# myChip register map
Vendor: ARM Ltd.; Series: ARMCM3; File version: 1.2
CPU: CM3 r2p1, little endian, no MPU, no FPU, 3 interrupt priority bits
Registers are 32-bit, read-write, reset 0x0 unless marked. A register's access mark holds for its fields unless they carry their own. Offsets are from the block's base; [hi:lo] are bit positions; {n}, {i} and the like mark numbered series.

## HRPWM_SLV0
Base 0x4003B100
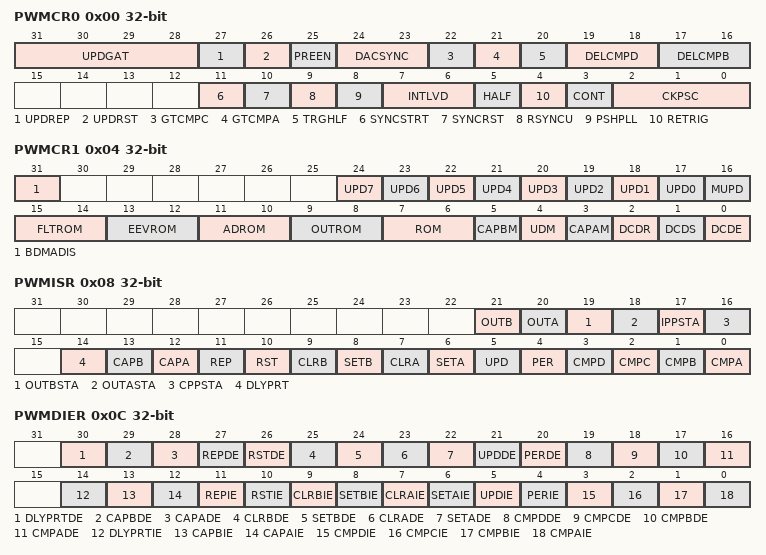
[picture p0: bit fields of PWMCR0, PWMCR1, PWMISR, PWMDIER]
0x00 PWMCR0 — HRPWM PWMx Control Register0
  [31:28] UPDGAT — 更新门控
  [27] UPDREP — PWMx Repetition 更新
  [26] UPDRST — PWMx Reset 更新
  [25] PREEN — PWMx 预加载使能
  [24:23] DACSYNC — DAC Trigger同步
  [22] GTCMPC — PWMx CMPC Greater Than 模式
  [21] GTCMPA — PWMx CMPA Greater Than 模式
  [20] TRGHLF — PWMx Triggered-half 模式
  [19:18] DELCMPD — PWMx CMPD Auto-Delayed 模式
  [17:16] DELCMPB — PWMx CMPB Auto-Delayed 模式
  [11] SYNCSTRT — 同步事件启动 PWMx
  [10] SYNCRST — 同步事件复位 PWMx
  [9] RSYNCU — PWMx 重同步更新
  [8] PSHPLL — PWMx Push-pull 模式
  [7:6] INTLVD — PWMx Interleaved 模式
  [5] HALF — PWMx Half 模式
  [4] RETRIG — PWMx 可重触发模式
  [3] CONT — PWMx 连续模式
  [2:0] CKPSC — PWMx 时钟预分频比
0x04 PWMCR1 — HRPWM PWMx Control Register1
  [31] BDMADIS — PWMx Burst DMA 禁止
  [n+17] UPD{n} (n=0..7) — PWM{n} 更新
  [16] MUPD — Master PWM 更新
  [15:14] FLTROM — 故障 Roll-Over 模式选择
  [13:12] EEVROM — 事件 Roll-Over 模式选择
  [11:10] ADROM — ADC Roll-Over 模式选择
  [9:8] OUTROM — 输出 Roll-Over 模式选择
  [7:6] ROM — Roll-Over 模式选择
  [5] CAPBM — Capture B 模式选择
  [4] UDM — Up-Down 模式选择
  [3] CAPAM — Capture A 模式选择
  [2] DCDR — DAC Reset Trigger 来源
  [1] DCDS — DAC Step Trigger 来源
  [0] DCDE — DAC Reset／Step Trigger 使能
0x08 PWMISR — HRPWM PWMx Interrupt Status Register
  [21] OUTB ro — OUTB 当前输出（输出级之前）
  [20] OUTA ro — OUTA 当前输出（输出级之前）
  [19] OUTBSTA ro — OUTB 输出状态（延迟空闲保护发生时）
  [18] OUTASTA ro — OUTA 输出状态（延迟空闲保护发生时）
  [17] IPPSTA ro — PushPull 输出状态（延迟空闲/均衡空闲保护发生时）
  [16] CPPSTA ro — PushPull 当前状态
  [14] DLYPRT — Delayed Protection 中断标志
  [13] CAPB — Capture B 中断标志
  [12] CAPA — Capture A 中断标志
  [11] REP — Repetition 中断标志
  [10] RST — Reset 中断标志
  [9] CLRB — Out B Clear 中断标志
  [8] SETB — Out B Set 中断标志
  [7] CLRA — Out A Clear 中断标志
  [6] SETA — Out A Set 中断标志
  [5] UPD — Update 中断标志
  [4] PER — Roll-Over 中断标志
  [3] CMPD — Compare D 中断标志
  [2] CMPC — Compare C 中断标志
  [1] CMPB — Compare B 中断标志
  [0] CMPA — Compare A 中断标志
0x0C PWMDIER — HRPWM PWMx DMA Interrupt Enable Register
  [30] DLYPRTDE — Delayed Protection DMA使能
  [29] CAPBDE — Capture B DMA使能
  [28] CAPADE — Capture A DMA使能
  [27] REPDE — Repetition DMA使能
  [26] RSTDE — Reset DMA使能
  [25] CLRBDE — Out B Clear DMA使能
  [24] SETBDE — Out B Set DMA使能
  [23] CLRADE — Out A Clear DMA使能
  [22] SETADE — Out A Set DMA使能
  [21] UPDDE — Update DMA使能
  [20] PERDE — Roll-Over DMA使能
  [19] CMPDDE — Compare D DMA使能
  [18] CMPCDE — Compare C DMA使能
  [17] CMPBDE — Compare B DMA使能
  [16] CMPADE — Compare A DMA使能
  [14] DLYPRTIE — Delayed Protection 中断使能
  [13] CAPBIE — Capture B 中断使能
  [12] CAPAIE — Capture A 中断使能
  [11] REPIE — Repetition 中断使能
  [10] RSTIE — Reset 中断使能
  [9] CLRBIE — Out B Clear 中断使能
  [8] SETBIE — Out B Set 中断使能
  [7] CLRAIE — Out A Clear 中断使能
  [6] SETAIE — Out A Set 中断使能
  [5] UPDIE — Update 中断使能
  [4] PERIE — Roll-Over 中断使能
  [3] CMPDIE — Compare D 中断使能
  [2] CMPCIE — Compare C 中断使能
  [1] CMPBIE — Compare B 中断使能
  [0] CMPAIE — Compare A 中断使能
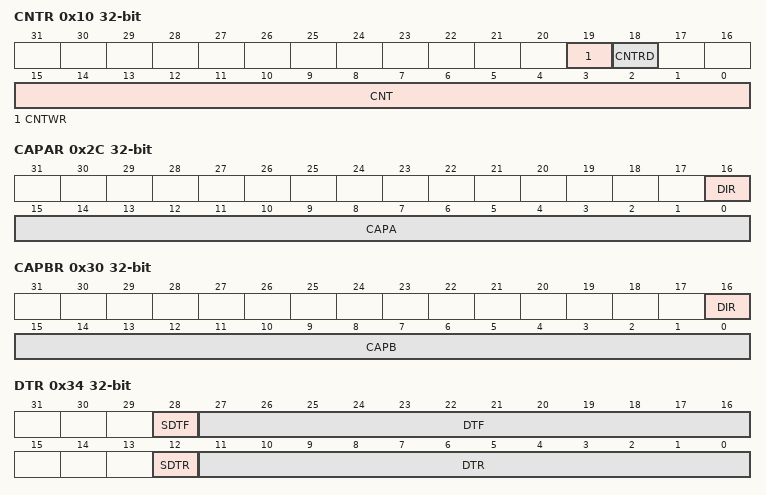
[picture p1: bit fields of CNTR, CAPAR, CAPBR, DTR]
0x10 CNTR — HRPWM PWMx Counter Register
  [19] CNTWR — PWMx Counter 写入
  [18] CNTRD — PWMx Counter 读取
  [15:0] CNT — PWMx Counter 数值
0x14 PERR — HRPWM PWMx Period Register
  [15:0] PER — PWMx Period 数值
0x18 REPR — HRPWM PWMx Repetition Register
  [7:0] REP — PWMx Repetition Period 数值
0x1C CMPAR — HRPWM PWMx Compare A Register
  [15:0] CMPA — PWMx Compare A 数值
0x20 CMPBR — HRPWM PWMx Compare B Register
  [15:0] CMPB — PWMx Compare B 数值
0x24 CMPCR — HRPWM PWMx Compare C Register
  [15:0] CMPC — PWMx Compare C 数值
0x28 CMPDR — HRPWM PWMx Compare D Register
  [15:0] CMPD — PWMx Compare D 数值
0x2C CAPAR — HRPWM PWMx Capture A Register
  [16] DIR ro — 捕获 A 方向
  [15:0] CAPA ro — 捕获 A 数值
0x30 CAPBR — HRPWM PWMx Capture B Register
  [16] DIR ro — 捕获 B 方向
  [15:0] CAPB ro — 捕获 B 数值
0x34 DTR — HRPWM PWMx DeadTime Register
  [28] SDTF — 下降沿死区符号
  [27:16] DTF — 下降沿死区时间
  [12] SDTR — 上升沿死区符号
  [11:0] DTR — 上升沿死区时间
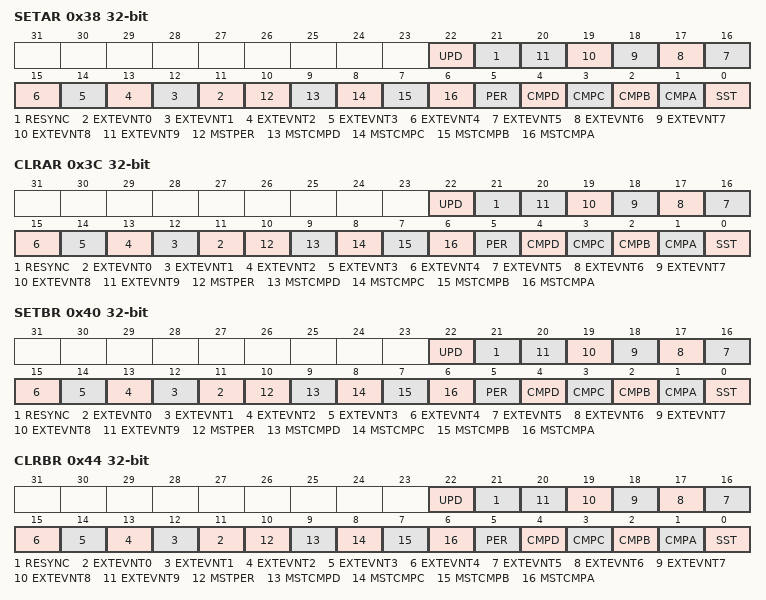
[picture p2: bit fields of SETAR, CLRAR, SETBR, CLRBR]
0x38 SETAR — HRPWM PWMx Output A Set Register
  [22] UPD — PWMx Update 事件使 PWMx Out A进入有效状态
  [21] RESYNC — Sync Input Event 事件使 PWMx Out A进入有效状态
  [n+11] EXTEVNT{n} (n=0..9) — PWMx Event {n} 事件使 PWMx Out A进入有效状态
  [10] MSTPER — Master PWM Period 事件使 PWMx Out A进入有效状态
  [9] MSTCMPD — Master PWM Compare D 事件使 PWMx Out A进入有效状态
  [8] MSTCMPC — Master PWM Compare C 事件使 PWMx Out A进入有效状态
  [7] MSTCMPB — Master PWM Compare B 事件使 PWMx Out A进入有效状态
  [6] MSTCMPA — Master PWM Compare A 事件使 PWMx Out A进入有效状态
  [5] PER — PWMx Roll-Over 事件使 PWMx Out A进入有效状态
  [4] CMPD — PWMx Compare D 事件使 PWMx Out A进入有效状态
  [3] CMPC — PWMx Compare C 事件使 PWMx Out A进入有效状态
  [2] CMPB — PWMx Compare B 事件使 PWMx Out A进入有效状态
  [1] CMPA — PWMx Compare A 事件使 PWMx Out A进入有效状态
  [0] SST — Software Set Trigger 事件使 PWMx Out A进入有效状态
0x3C CLRAR — HRPWM PWMx Output A Clear Register
  [22] UPD — PWMx Update 事件使 PWMx Out A进入无效状态
  [21] RESYNC — Sync Input Event 事件使 PWMx Out A进入无效状态
  [n+11] EXTEVNT{n} (n=0..9) — PWMx Event {n} 事件使 PWMx Out A进入无效状态
  [10] MSTPER — Master PWM Period 事件使 PWMx Out A进入无效状态
  [9] MSTCMPD — Master PWM Compare D 事件使 PWMx Out A进入无效状态
  [8] MSTCMPC — Master PWM Compare C 事件使 PWMx Out A进入无效状态
  [7] MSTCMPB — Master PWM Compare B 事件使 PWMx Out A进入无效状态
  [6] MSTCMPA — Master PWM Compare A 事件使 PWMx Out A进入无效状态
  [5] PER — PWMx Roll-Over 事件使 PWMx Out A进入无效状态
  [4] CMPD — PWMx Compare D 事件使 PWMx Out A进入无效状态
  [3] CMPC — PWMx Compare C 事件使 PWMx Out A进入无效状态
  [2] CMPB — PWMx Compare B 事件使 PWMx Out A进入无效状态
  [1] CMPA — PWMx Compare A 事件使 PWMx Out A进入无效状态
  [0] SST — Software Set Trigger 事件使 PWMx Out A进入无效状态
0x40 SETBR — HRPWM PWMx Output B Set Register
  [22] UPD — PWMx Update 事件使 PWMx Out B进入有效状态
  [21] RESYNC — Sync Input Event 事件使 PWMx Out B进入有效状态
  [n+11] EXTEVNT{n} (n=0..9) — PWMx Event {n} 事件使 PWMx Out B进入有效状态
  [10] MSTPER — Master PWM Period 事件使 PWMx Out B进入有效状态
  [9] MSTCMPD — Master PWM Compare D 事件使 PWMx Out B进入有效状态
  [8] MSTCMPC — Master PWM Compare C 事件使 PWMx Out B进入有效状态
  [7] MSTCMPB — Master PWM Compare B 事件使 PWMx Out B进入有效状态
  [6] MSTCMPA — Master PWM Compare A 事件使 PWMx Out B进入有效状态
  [5] PER — PWMx Roll-Over 事件使 PWMx Out B进入有效状态
  [4] CMPD — PWMx Compare D 事件使 PWMx Out B进入有效状态
  [3] CMPC — PWMx Compare C 事件使 PWMx Out B进入有效状态
  [2] CMPB — PWMx Compare B 事件使 PWMx Out B进入有效状态
  [1] CMPA — PWMx Compare A 事件使 PWMx Out B进入有效状态
  [0] SST — Software Set Trigger 事件使 PWMx Out B进入有效状态
0x44 CLRBR — HRPWM PWMx Output B Clear Register
  [22] UPD — PWMx Update 事件使 PWMx Out B进入无效状态
  [21] RESYNC — Sync Input Event 事件使 PWMx Out B进入无效状态
  [n+11] EXTEVNT{n} (n=0..9) — PWMx Event {n} 事件使 PWMx Out B进入无效状态
  [10] MSTPER — Master PWM Period 事件使 PWMx Out B进入无效状态
  [9] MSTCMPD — Master PWM Compare D 事件使 PWMx Out B进入无效状态
  [8] MSTCMPC — Master PWM Compare C 事件使 PWMx Out B进入无效状态
  [7] MSTCMPB — Master PWM Compare B 事件使 PWMx Out B进入无效状态
  [6] MSTCMPA — Master PWM Compare A 事件使 PWMx Out B进入无效状态
  [5] PER — PWMx Roll-Over 事件使 PWMx Out B进入无效状态
  [4] CMPD — PWMx Compare D 事件使 PWMx Out B进入无效状态
  [3] CMPC — PWMx Compare C 事件使 PWMx Out B进入无效状态
  [2] CMPB — PWMx Compare B 事件使 PWMx Out B进入无效状态
  [1] CMPA — PWMx Compare A 事件使 PWMx Out B进入无效状态
  [0] SST — Software Set Trigger 事件使 PWMx Out B进入无效状态
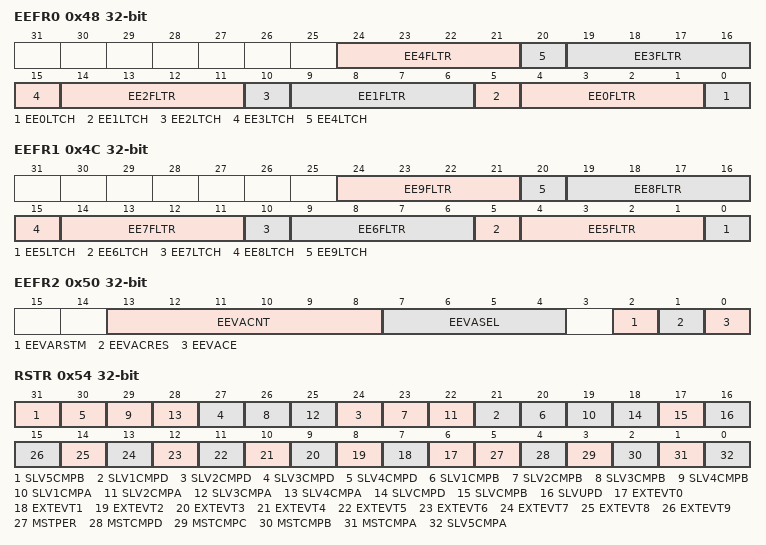
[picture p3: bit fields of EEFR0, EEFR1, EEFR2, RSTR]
0x48 EEFR0 — HRPWM PWMx External Event Register0
  [5n+4:5n+1] EE{n}FLTR (n=0..4) — Event {n} 滤波位
  [5n] EE{n}LTCH (n=0..4) — Event {n} 锁存位
0x4C EEFR1 — HRPWM PWMx External Event Register1
  [5n-21:5n-24] EE{n}FLTR (n=5..9) — Event {n} 滤波位
  [5n-25] EE{n}LTCH (n=5..9) — Event {n} 锁存位
0x50 EEFR2 — HRPWM PWMx External Event Register2
  [13:8] EEVACNT — Event A 计数阈值
  [7:4] EEVASEL — Event A 来源选择
  [2] EEVARSTM — Event A计数复位模式
  [1] EEVACRES — Event A 计数复位
  [0] EEVACE — Event A 计数使能
0x54 RSTR — HRPWM PWMx Reset Register
  [31] SLV5CMPB — PWM5 Compare B事件使 PWMx 计数器复位
  [3n+18] SLV{n}CMPD (n=1..4) — PWM{n} Compare D事件使 PWMx 计数器复位
  [3n+17] SLV{n}CMPB (n=1..4) — PWM{n} Compare B事件使 PWMx 计数器复位
  [3n+16] SLV{n}CMPA (n=1..4) — PWM{n} Compare A事件使 PWMx 计数器复位
  [18] SLVCMPD — PWMx Compare D事件使 PWMx 计数器复位
  [17] SLVCMPB — PWMx Compare B事件使 PWMx 计数器复位
  [16] SLVUPD — PWMx Update事件使 PWMx 计数器复位
  [n+6] EXTEVT{n} (n=0..9) — PWMx Event {n}事件使 PWMx 计数器复位
  [5] MSTPER — Master PWM Period事件使 PWMx 计数器复位
  [4] MSTCMPD — Master PWM Compare D事件使 PWMx 计数器复位
  [3] MSTCMPC — Master PWM Compare C事件使 PWMx 计数器复位
  [2] MSTCMPB — Master PWM Compare B事件使 PWMx 计数器复位
  [1] MSTCMPA — Master PWM Compare A事件使 PWMx 计数器复位
  [0] SLV5CMPA — PWM5 Compare A事件使 PWMx 计数器复位
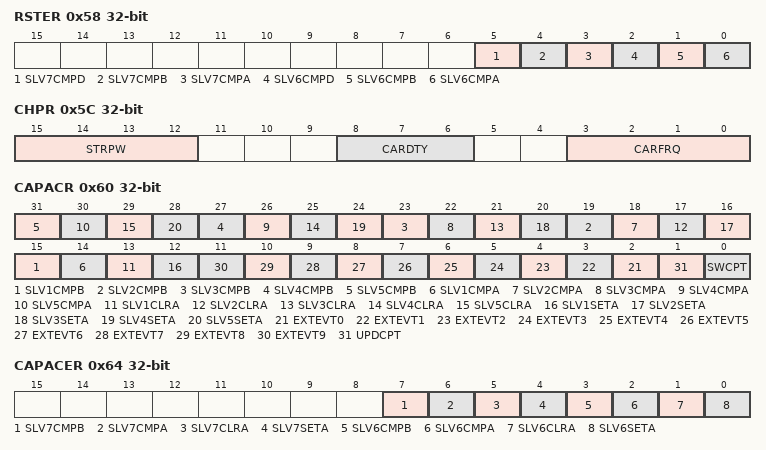
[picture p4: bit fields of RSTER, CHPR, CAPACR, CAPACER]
0x58 RSTER — HRPWM PWMx Reset Extended Register
  [5] SLV7CMPD — PWM7 Compare D事件使 PWMx 计数器复位
  [4] SLV7CMPB — PWM7 Compare B事件使 PWMx 计数器复位
  [3] SLV7CMPA — PWM7 Compare A事件使 PWMx 计数器复位
  [2] SLV6CMPD — PWM6 Compare D事件使 PWMx 计数器复位
  [1] SLV6CMPB — PWM6 Compare B事件使 PWMx 计数器复位
  [0] SLV6CMPA — PWM6 Compare A事件使 PWMx 计数器复位
0x5C CHPR — HRPWM PWMx Chopper Register
  [15:12] STRPW — PWMx 启动脉冲宽度
  [8:6] CARDTY — PWMx 斩波占空比值
  [3:0] CARFRQ — PWMx 载波频率值
0x60 CAPACR — HRPWM PWMx Capture A Control Register
  [4n+11] SLV{n}CMPB (n=1..5) — PWM{n} Compare B 事件触发 Capture A 事件
  [4n+10] SLV{n}CMPA (n=1..5) — PWM{n} Compare A 事件触发 Capture A 事件
  [4n+9] SLV{n}CLRA (n=1..5) — PWM{n} OutA Clr 事件触发 Capture A 事件
  [4n+8] SLV{n}SETA (n=1..5) — PWM{n} OutA Set 事件触发 Capture A 事件
  [n+2] EXTEVT{n} (n=0..9) — PWMx Event {n} 事件触发 Capture A 事件
  [1] UPDCPT — PWMx Update 事件触发 Capture A 事件
  [0] SWCPT — Software Capture 事件触发 Capture A 事件
0x64 CAPACER — HRPWM PWMx Capture A Control Extended Register
  [7] SLV7CMPB — PWM7 Compare B 事件触发 Capture A 事件
  [6] SLV7CMPA — PWM7 Compare A 事件触发 Capture A 事件
  [5] SLV7CLRA — PWM7 OutA Clr 事件触发 Capture A 事件
  [4] SLV7SETA — PWM7 OutA Set 事件触发 Capture A 事件
  [3] SLV6CMPB — PWM6 Compare B 事件触发 Capture A 事件
  [2] SLV6CMPA — PWM6 Compare A 事件触发 Capture A 事件
  [1] SLV6CLRA — PWM6 OutA Clr 事件触发 Capture A 事件
  [0] SLV6SETA — PWM6 OutA Set 事件触发 Capture A 事件
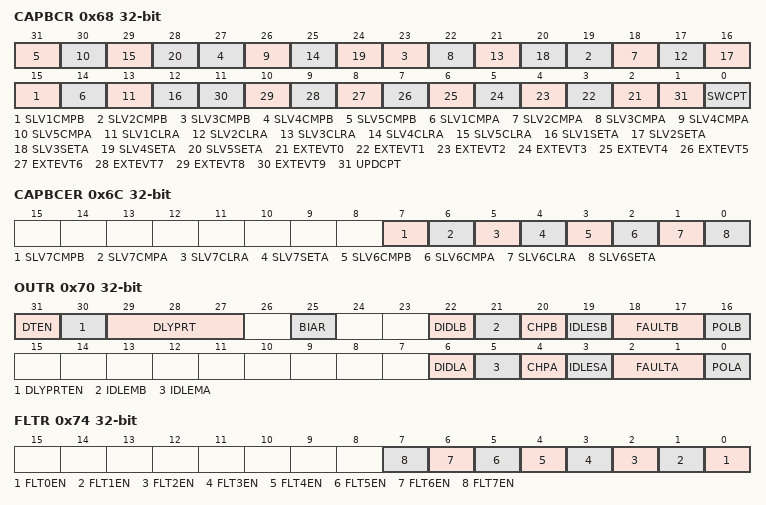
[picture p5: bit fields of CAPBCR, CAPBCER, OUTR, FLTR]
0x68 CAPBCR — HRPWM PWMx Capture B Control Register
  [4n+11] SLV{n}CMPB (n=1..5) — PWM{n} Compare B 事件触发 Capture B 事件
  [4n+10] SLV{n}CMPA (n=1..5) — PWM{n} Compare A 事件触发 Capture B 事件
  [4n+9] SLV{n}CLRA (n=1..5) — PWM{n} OutA Clr 事件触发 Capture B 事件
  [4n+8] SLV{n}SETA (n=1..5) — PWM{n} OutA Set 事件触发 Capture B 事件
  [n+2] EXTEVT{n} (n=0..9) — PWMx Event {n} 事件触发 Capture B 事件
  [1] UPDCPT — PWMx Update 事件触发 Capture B 事件
  [0] SWCPT — Software Capture 事件触发 Capture B 事件
0x6C CAPBCER — HRPWM PWMx Capture B Control Extended Register
  [7] SLV7CMPB — PWM7 Compare B 事件触发 Capture B 事件
  [6] SLV7CMPA — PWM7 Compare A 事件触发 Capture B 事件
  [5] SLV7CLRA — PWM7 OutA Clr 事件触发 Capture B 事件
  [4] SLV7SETA — PWM7 OutA Set 事件触发 Capture B 事件
  [3] SLV6CMPB — PWM6 Compare B 事件触发 Capture B 事件
  [2] SLV6CMPA — PWM6 Compare A 事件触发 Capture B 事件
  [1] SLV6CLRA — PWM6 OutA Clr 事件触发 Capture B 事件
  [0] SLV6SETA — PWM6 OutA Set 事件触发 Capture B 事件
0x70 OUTR — HRPWM PWMx Output Register
  [31] DTEN — 死区使能
  [30] DLYPRTEN — 延迟保护使能
  [29:27] DLYPRT — 延迟保护机制
  [25] BIAR — 均衡空闲自动恢复
  [22] DIDLB — 输出 B 空闲模式死区使能
  [21] IDLEMB — 输出 B 空闲模式
  [20] CHPB — 输出 B 斩波使能
  [19] IDLESB — 输出 B 空闲状态
  [18:17] FAULTB — 输出 B 故障状态
  [16] POLB — 输出 B 极性
  [6] DIDLA — 输出 A 空闲模式死区使能
  [5] IDLEMA — 输出 A 空闲模式
  [4] CHPA — 输出 A 斩波使能
  [3] IDLESA — 输出 A 空闲状态
  [2:1] FAULTA — 输出 A 故障电平
  [0] POLA — 输出 A 极性
0x74 FLTR — HRPWM PWMx Fault Register
  [n] FLT{n}EN (n=0..7) — Fault {n} 使能
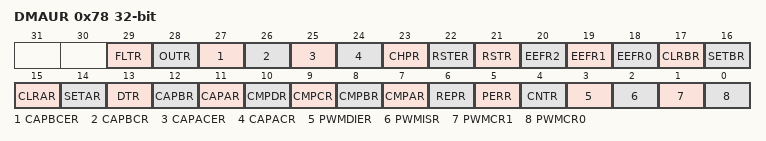
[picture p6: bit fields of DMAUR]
0x78 DMAUR — HRPWM PWMx System DMA Update Register
  [29] FLTR — FLTR 寄存器支持 System DMA 写入DMADR并更新
  [28] OUTR — OUTR 寄存器支持 System DMA 写入DMADR并更新
  [27] CAPBCER — CAPBCER 寄存器支持 System DMA 写入DMADR并更新
  [26] CAPBCR — CAPBCR 寄存器支持 System DMA 写入DMADR并更新
  [25] CAPACER — CAPACER 寄存器支持 System DMA 写入DMADR并更新
  [24] CAPACR — CAPACR 寄存器支持 System DMA 写入DMADR并更新
  [23] CHPR — CHPR 寄存器支持 System DMA 写入DMADR并更新
  [22] RSTER — RSTER 寄存器支持 System DMA 写入DMADR并更新
  [21] RSTR — RSTR 寄存器支持 System DMA 写入DMADR并更新
  [20] EEFR2 — EEFR2 寄存器支持 System DMA 写入DMADR并更新
  [19] EEFR1 — EEFR1 寄存器支持 System DMA 写入DMADR并更新
  [18] EEFR0 — EEFR0 寄存器支持 System DMA 写入DMADR并更新
  [17] CLRBR — CLRBR 寄存器支持 System DMA 写入DMADR并更新
  [16] SETBR — SETBR 寄存器支持 System DMA 写入DMADR并更新
  [15] CLRAR — CLRAR 寄存器支持 System DMA 写入DMADR并更新
  [14] SETAR — SETAR 寄存器支持 System DMA 写入DMADR并更新
  [13] DTR — DTR 寄存器支持 System DMA 写入DMADR并更新
  [12] CAPBR — CAPBR 寄存器支持 System DMA 从DMADR读取数据
  [11] CAPAR — CAPAR 寄存器支持 System DMA 从DMADR读取数据
  [10] CMPDR — CMPDR 寄存器支持 System DMA 写入DMADR并更新
  [9] CMPCR — CMPCR 寄存器支持 System DMA 写入DMADR并更新
  [8] CMPBR — CMPBR 寄存器支持 System DMA 写入DMADR并更新
  [7] CMPAR — CMPAR 寄存器支持 System DMA 写入DMADR并更新
  [6] REPR — REPR 寄存器支持 System DMA 写入DMADR并更新
  [5] PERR — PERR 寄存器支持 System DMA 写入DMADR并更新
  [4] CNTR — CNTR 寄存器支持 System DMA 写入DMADR并更新
  [3] PWMDIER — PWMDIER 寄存器支持 System DMA 写入DMADR并更新
  [2] PWMISR — PWMISR 寄存器支持 System DMA 写入DMADR并更新
  [1] PWMCR1 — PWMCR1 寄存器支持 System DMA 写入DMADR并更新
  [0] PWMCR0 — PWMCR0 寄存器支持 System DMA 写入DMADR并更新
0x7C DMADR — HRPWM PWMx System DMA Data Register
  [31:0] DMADR — System DMA 数据地址

## HRPWM_SLV1
Base 0x4003B200
Registers as HRPWM_SLV0; these are added or differ:
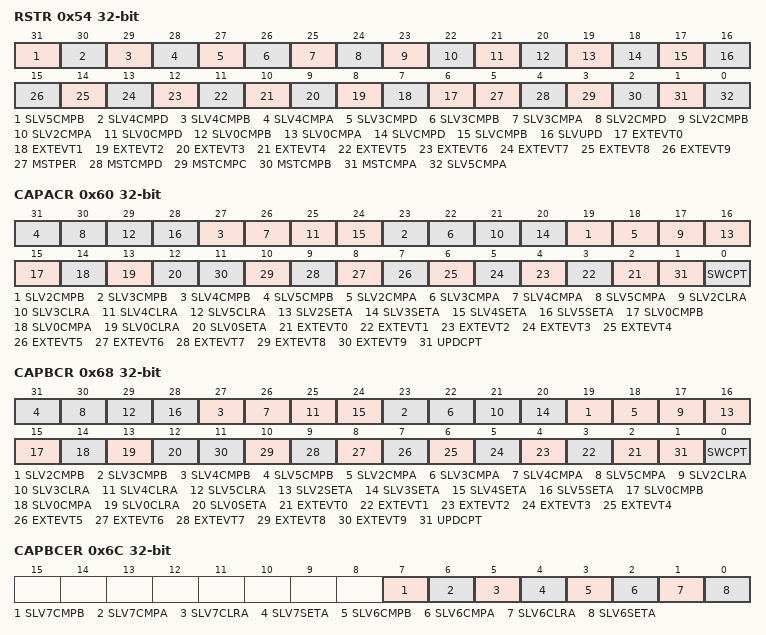
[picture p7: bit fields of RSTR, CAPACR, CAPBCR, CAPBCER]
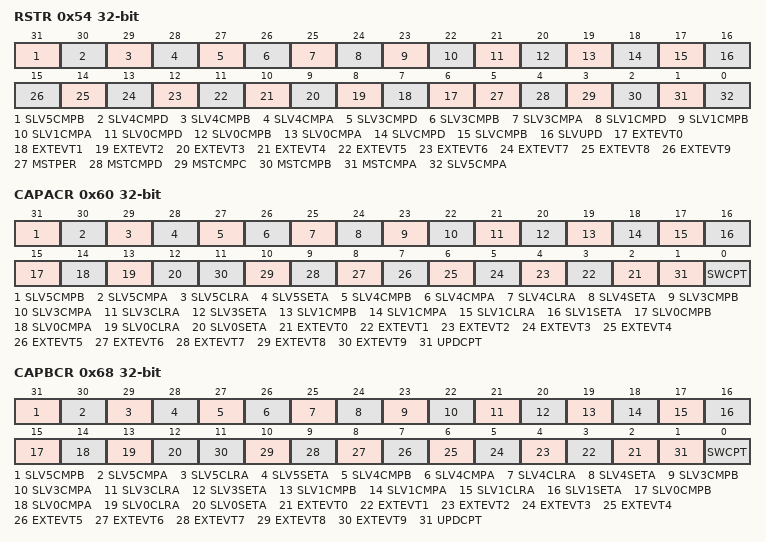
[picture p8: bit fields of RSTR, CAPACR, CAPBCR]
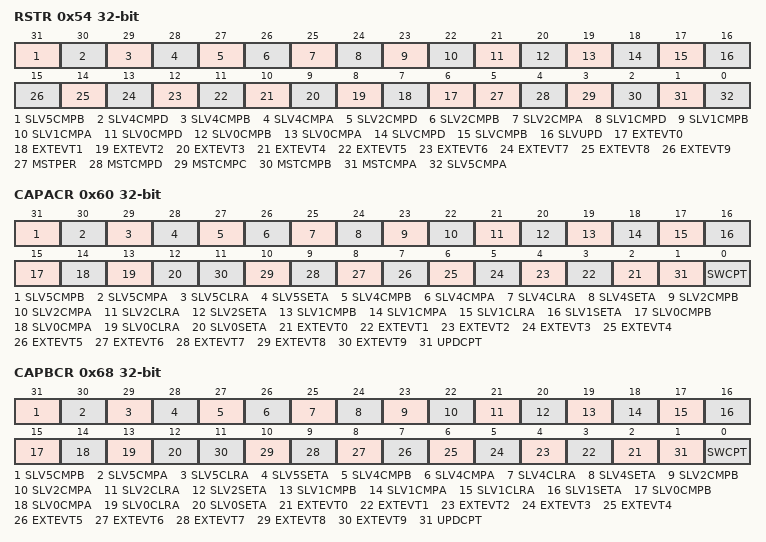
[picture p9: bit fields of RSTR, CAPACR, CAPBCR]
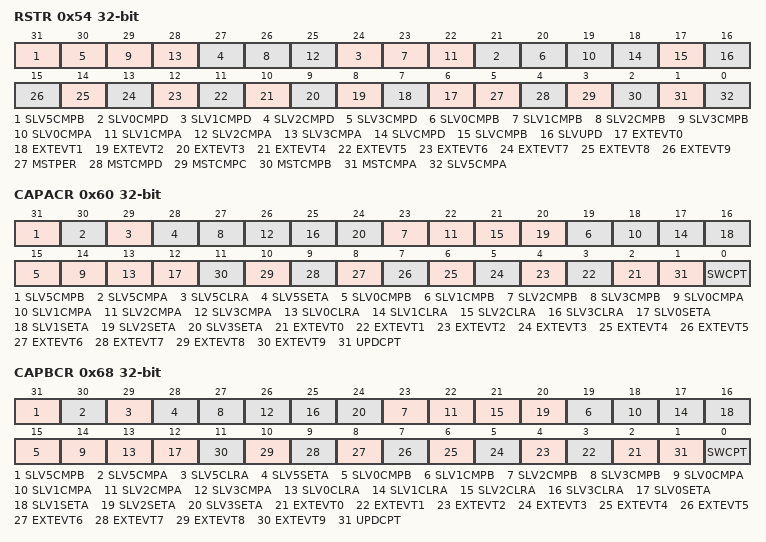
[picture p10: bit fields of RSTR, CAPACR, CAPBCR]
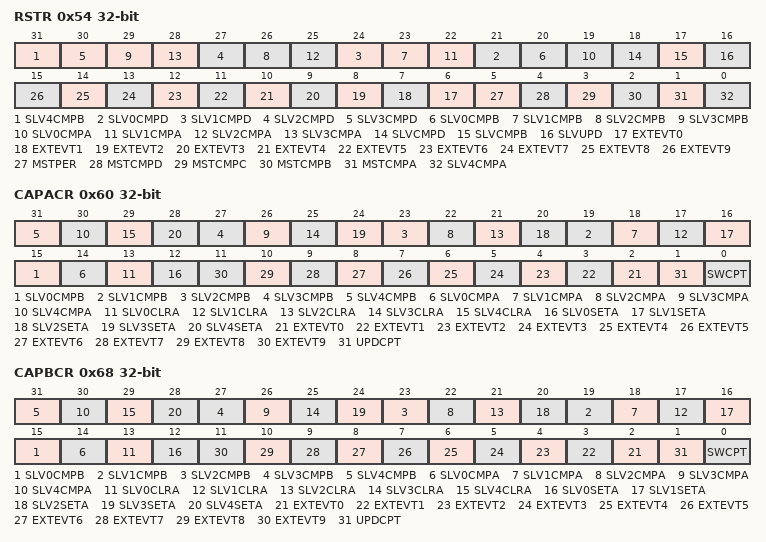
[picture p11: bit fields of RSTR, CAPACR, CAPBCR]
0x54 RSTR — HRPWM PWMx Reset Register
  [31] SLV5CMPB — PWM5 Compare B事件使 PWMx 计数器复位
  [30] SLV4CMPD — PWM4 Compare D事件使 PWMx 计数器复位
  [29] SLV4CMPB — PWM4 Compare B事件使 PWMx 计数器复位
  [28] SLV4CMPA — PWM4 Compare A事件使 PWMx 计数器复位
  [27] SLV3CMPD — PWM3 Compare D事件使 PWMx 计数器复位
  [26] SLV3CMPB — PWM3 Compare B事件使 PWMx 计数器复位
  [25] SLV3CMPA — PWM3 Compare A事件使 PWMx 计数器复位
  [24] SLV2CMPD — PWM2 Compare D事件使 PWMx 计数器复位
  [23] SLV2CMPB — PWM2 Compare B事件使 PWMx 计数器复位
  [22] SLV2CMPA — PWM2 Compare A事件使 PWMx 计数器复位
  [21] SLV0CMPD — PWM0 Compare D事件使 PWMx 计数器复位
  [20] SLV0CMPB — PWM0 Compare B事件使 PWMx 计数器复位
  [19] SLV0CMPA — PWM0 Compare A事件使 PWMx 计数器复位
  [18] SLVCMPD — PWMx Compare D事件使 PWMx 计数器复位
  [17] SLVCMPB — PWMx Compare B事件使 PWMx 计数器复位
  [16] SLVUPD — PWMx Update事件使 PWMx 计数器复位
  [n+6] EXTEVT{n} (n=0..9) — PWMx Event {n}事件使 PWMx 计数器复位
  [5] MSTPER — Master PWM Period事件使 PWMx 计数器复位
  [4] MSTCMPD — Master PWM Compare D事件使 PWMx 计数器复位
  [3] MSTCMPC — Master PWM Compare C事件使 PWMx 计数器复位
  [2] MSTCMPB — Master PWM Compare B事件使 PWMx 计数器复位
  [1] MSTCMPA — Master PWM Compare A事件使 PWMx 计数器复位
  [0] SLV5CMPA — PWM5 Compare A事件使 PWMx 计数器复位
0x60 CAPACR — HRPWM PWMx Capture A Control Register
  [4n+11] SLV{n}CMPB (n=2..5) — PWM{n} Compare B 事件触发 Capture A 事件
  [4n+10] SLV{n}CMPA (n=2..5) — PWM{n} Compare A 事件触发 Capture A 事件
  [4n+9] SLV{n}CLRA (n=2..5) — PWM{n} OutA Clr 事件触发 Capture A 事件
  [4n+8] SLV{n}SETA (n=2..5) — PWM{n} OutA Set 事件触发 Capture A 事件
  [15] SLV0CMPB — PWM0 Compare B 事件触发 Capture A 事件
  [14] SLV0CMPA — PWM0 Compare A 事件触发 Capture A 事件
  [13] SLV0CLRA — PWM0 OutA Clr 事件触发 Capture A 事件
  [12] SLV0SETA — PWM0 OutA Set 事件触发 Capture A 事件
  [n+2] EXTEVT{n} (n=0..9) — PWMx Event {n} 事件触发 Capture A 事件
  [1] UPDCPT — PWMx Update 事件触发 Capture A 事件
  [0] SWCPT — Software Capture 事件触发 Capture A 事件
0x68 CAPBCR — HRPWM PWMx Capture B Control Register
  [4n+11] SLV{n}CMPB (n=2..5) — PWM{n} Compare B 事件触发 Capture B 事件
  [4n+10] SLV{n}CMPA (n=2..5) — PWM{n} Compare A 事件触发 Capture B 事件
  [4n+9] SLV{n}CLRA (n=2..5) — PWM{n} OutA Clr 事件触发 Capture B 事件
  [4n+8] SLV{n}SETA (n=2..5) — PWM{n} OutA Set 事件触发 Capture B 事件
  [15] SLV0CMPB — PWM0 Compare B 事件触发 Capture B 事件
  [14] SLV0CMPA — PWM0 Compare A 事件触发 Capture B 事件
  [13] SLV0CLRA — PWM0 OutA Clr 事件触发 Capture B 事件
  [12] SLV0SETA — PWM0 OutA Set 事件触发 Capture B 事件
  [n+2] EXTEVT{n} (n=0..9) — PWMx Event {n} 事件触发 Capture B 事件
  [1] UPDCPT — PWMx Update 事件触发 Capture B 事件
  [0] SWCPT — Software Capture 事件触发 Capture B 事件
0x6C CAPBCER — HRPWM PWMx Capture B Control Extended Register
  [7] SLV7CMPB — Reserved
  [6] SLV7CMPA — PWM7 Compare A 事件触发 Capture B 事件
  [5] SLV7CLRA — PWM7 OutA Clr 事件触发 Capture B 事件
  [4] SLV7SETA — PWM7 OutA Set 事件触发 Capture B 事件
  [3] SLV6CMPB — PWM6 Compare B 事件触发 Capture B 事件
  [2] SLV6CMPA — PWM6 Compare A 事件触发 Capture B 事件
  [1] SLV6CLRA — PWM6 OutA Clr 事件触发 Capture B 事件
  [0] SLV6SETA — PWM6 OutA Set 事件触发 Capture B 事件

## HRPWM_SLV2
Base 0x4003B300
Registers as HRPWM_SLV0; these are added or differ:
0x54 RSTR — HRPWM PWMx Reset Register
  [31] SLV5CMPB — PWM5 Compare B事件使 PWMx 计数器复位
  [30] SLV4CMPD — PWM4 Compare D事件使 PWMx 计数器复位
  [29] SLV4CMPB — PWM4 Compare B事件使 PWMx 计数器复位
  [28] SLV4CMPA — PWM4 Compare A事件使 PWMx 计数器复位
  [27] SLV3CMPD — PWM3 Compare D事件使 PWMx 计数器复位
  [26] SLV3CMPB — PWM3 Compare B事件使 PWMx 计数器复位
  [25] SLV3CMPA — PWM3 Compare A事件使 PWMx 计数器复位
  [24] SLV1CMPD — PWM1 Compare D事件使 PWMx 计数器复位
  [23] SLV1CMPB — PWM1 Compare B事件使 PWMx 计数器复位
  [22] SLV1CMPA — PWM1 Compare A事件使 PWMx 计数器复位
  [21] SLV0CMPD — PWM0 Compare D事件使 PWMx 计数器复位
  [20] SLV0CMPB — PWM0 Compare B事件使 PWMx 计数器复位
  [19] SLV0CMPA — PWM0 Compare A事件使 PWMx 计数器复位
  [18] SLVCMPD — PWMx Compare D事件使 PWMx 计数器复位
  [17] SLVCMPB — PWMx Compare B事件使 PWMx 计数器复位
  [16] SLVUPD — PWMx Update事件使 PWMx 计数器复位
  [n+6] EXTEVT{n} (n=0..9) — PWMx Event {n}事件使 PWMx 计数器复位
  [5] MSTPER — Master PWM Period事件使 PWMx 计数器复位
  [4] MSTCMPD — Master PWM Compare D事件使 PWMx 计数器复位
  [3] MSTCMPC — Master PWM Compare C事件使 PWMx 计数器复位
  [2] MSTCMPB — Master PWM Compare B事件使 PWMx 计数器复位
  [1] MSTCMPA — Master PWM Compare A事件使 PWMx 计数器复位
  [0] SLV5CMPA — PWM5 Compare A事件使 PWMx 计数器复位
0x60 CAPACR — HRPWM PWMx Capture A Control Register
  [31] SLV5CMPB — PWM5 Compare B 事件触发 Capture A 事件
  [30] SLV5CMPA — PWM5 Compare A 事件触发 Capture A 事件
  [29] SLV5CLRA — PWM5 OutA Clr 事件触发 Capture A 事件
  [28] SLV5SETA — PWM5 OutA Set 事件触发 Capture A 事件
  [27] SLV4CMPB — PWM4 Compare B 事件触发 Capture A 事件
  [26] SLV4CMPA — PWM4 Compare A 事件触发 Capture A 事件
  [25] SLV4CLRA — PWM4 OutA Clr 事件触发 Capture A 事件
  [24] SLV4SETA — PWM4 OutA Set 事件触发 Capture A 事件
  [23] SLV3CMPB — PWM3 Compare B 事件触发 Capture A 事件
  [22] SLV3CMPA — PWM3 Compare A 事件触发 Capture A 事件
  [21] SLV3CLRA — PWM3 OutA Clr 事件触发 Capture A 事件
  [20] SLV3SETA — PWM3 OutA Set 事件触发 Capture A 事件
  [19] SLV1CMPB — PWM1 Compare B 事件触发 Capture A 事件
  [18] SLV1CMPA — PWM1 Compare A 事件触发 Capture A 事件
  [17] SLV1CLRA — PWM1 OutA Clr 事件触发 Capture A 事件
  [16] SLV1SETA — PWM1 OutA Set 事件触发 Capture A 事件
  [15] SLV0CMPB — PWM0 Compare B 事件触发 Capture A 事件
  [14] SLV0CMPA — PWM0 Compare A 事件触发 Capture A 事件
  [13] SLV0CLRA — PWM0 OutA Clr 事件触发 Capture A 事件
  [12] SLV0SETA — PWM0 OutA Set 事件触发 Capture A 事件
  [n+2] EXTEVT{n} (n=0..9) — PWMx Event {n} 事件触发 Capture A 事件
  [1] UPDCPT — PWMx Update 事件触发 Capture A 事件
  [0] SWCPT — Software Capture 事件触发 Capture A 事件
0x68 CAPBCR — HRPWM PWMx Capture B Control Register
  [31] SLV5CMPB — PWM5 Compare B 事件触发 Capture B 事件
  [30] SLV5CMPA — PWM5 Compare A 事件触发 Capture B 事件
  [29] SLV5CLRA — PWM5 OutA Clr 事件触发 Capture B 事件
  [28] SLV5SETA — PWM5 OutA Set 事件触发 Capture B 事件
  [27] SLV4CMPB — PWM4 Compare B 事件触发 Capture B 事件
  [26] SLV4CMPA — PWM4 Compare A 事件触发 Capture B 事件
  [25] SLV4CLRA — PWM4 OutA Clr 事件触发 Capture B 事件
  [24] SLV4SETA — PWM4 OutA Set 事件触发 Capture B 事件
  [23] SLV3CMPB — PWM3 Compare B 事件触发 Capture B 事件
  [22] SLV3CMPA — PWM3 Compare A 事件触发 Capture B 事件
  [21] SLV3CLRA — PWM3 OutA Clr 事件触发 Capture B 事件
  [20] SLV3SETA — PWM3 OutA Set 事件触发 Capture B 事件
  [19] SLV1CMPB — PWM1 Compare B 事件触发 Capture B 事件
  [18] SLV1CMPA — PWM1 Compare A 事件触发 Capture B 事件
  [17] SLV1CLRA — PWM1 OutA Clr 事件触发 Capture B 事件
  [16] SLV1SETA — PWM1 OutA Set 事件触发 Capture B 事件
  [15] SLV0CMPB — PWM0 Compare B 事件触发 Capture B 事件
  [14] SLV0CMPA — PWM0 Compare A 事件触发 Capture B 事件
  [13] SLV0CLRA — PWM0 OutA Clr 事件触发 Capture B 事件
  [12] SLV0SETA — PWM0 OutA Set 事件触发 Capture B 事件
  [n+2] EXTEVT{n} (n=0..9) — PWMx Event {n} 事件触发 Capture B 事件
  [1] UPDCPT — PWMx Update 事件触发 Capture B 事件
  [0] SWCPT — Software Capture 事件触发 Capture B 事件

## HRPWM_SLV3
Base 0x4003B400
Registers as HRPWM_SLV0; these are added or differ:
0x54 RSTR — HRPWM PWMx Reset Register
  [31] SLV5CMPB — PWM5 Compare B事件使 PWMx 计数器复位
  [30] SLV4CMPD — PWM4 Compare D事件使 PWMx 计数器复位
  [29] SLV4CMPB — PWM4 Compare B事件使 PWMx 计数器复位
  [28] SLV4CMPA — PWM4 Compare A事件使 PWMx 计数器复位
  [27] SLV2CMPD — PWM2 Compare D事件使 PWMx 计数器复位
  [26] SLV2CMPB — PWM2 Compare B事件使 PWMx 计数器复位
  [25] SLV2CMPA — PWM2 Compare A事件使 PWMx 计数器复位
  [24] SLV1CMPD — PWM1 Compare D事件使 PWMx 计数器复位
  [23] SLV1CMPB — PWM1 Compare B事件使 PWMx 计数器复位
  [22] SLV1CMPA — PWM1 Compare A事件使 PWMx 计数器复位
  [21] SLV0CMPD — PWM0 Compare D事件使 PWMx 计数器复位
  [20] SLV0CMPB — PWM0 Compare B事件使 PWMx 计数器复位
  [19] SLV0CMPA — PWM0 Compare A事件使 PWMx 计数器复位
  [18] SLVCMPD — PWMx Compare D事件使 PWMx 计数器复位
  [17] SLVCMPB — PWMx Compare B事件使 PWMx 计数器复位
  [16] SLVUPD — PWMx Update事件使 PWMx 计数器复位
  [n+6] EXTEVT{n} (n=0..9) — PWMx Event {n}事件使 PWMx 计数器复位
  [5] MSTPER — Master PWM Period事件使 PWMx 计数器复位
  [4] MSTCMPD — Master PWM Compare D事件使 PWMx 计数器复位
  [3] MSTCMPC — Master PWM Compare C事件使 PWMx 计数器复位
  [2] MSTCMPB — Master PWM Compare B事件使 PWMx 计数器复位
  [1] MSTCMPA — Master PWM Compare A事件使 PWMx 计数器复位
  [0] SLV5CMPA — PWM5 Compare A事件使 PWMx 计数器复位
0x60 CAPACR — HRPWM PWMx Capture A Control Register
  [31] SLV5CMPB — PWM5 Compare B 事件触发 Capture A 事件
  [30] SLV5CMPA — PWM5 Compare A 事件触发 Capture A 事件
  [29] SLV5CLRA — PWM5 OutA Clr 事件触发 Capture A 事件
  [28] SLV5SETA — PWM5 OutA Set 事件触发 Capture A 事件
  [27] SLV4CMPB — PWM4 Compare B 事件触发 Capture A 事件
  [26] SLV4CMPA — PWM4 Compare A 事件触发 Capture A 事件
  [25] SLV4CLRA — PWM4 OutA Clr 事件触发 Capture A 事件
  [24] SLV4SETA — PWM4 OutA Set 事件触发 Capture A 事件
  [23] SLV2CMPB — PWM2 Compare B 事件触发 Capture A 事件
  [22] SLV2CMPA — PWM2 Compare A 事件触发 Capture A 事件
  [21] SLV2CLRA — PWM2 OutA Clr 事件触发 Capture A 事件
  [20] SLV2SETA — PWM2 OutA Set 事件触发 Capture A 事件
  [19] SLV1CMPB — PWM1 Compare B 事件触发 Capture A 事件
  [18] SLV1CMPA — PWM1 Compare A 事件触发 Capture A 事件
  [17] SLV1CLRA — PWM1 OutA Clr 事件触发 Capture A 事件
  [16] SLV1SETA — PWM1 OutA Set 事件触发 Capture A 事件
  [15] SLV0CMPB — PWM0 Compare B 事件触发 Capture A 事件
  [14] SLV0CMPA — PWM0 Compare A 事件触发 Capture A 事件
  [13] SLV0CLRA — PWM0 OutA Clr 事件触发 Capture A 事件
  [12] SLV0SETA — PWM0 OutA Set 事件触发 Capture A 事件
  [n+2] EXTEVT{n} (n=0..9) — PWMx Event {n} 事件触发 Capture A 事件
  [1] UPDCPT — PWMx Update 事件触发 Capture A 事件
  [0] SWCPT — Software Capture 事件触发 Capture A 事件
0x68 CAPBCR — HRPWM PWMx Capture B Control Register
  [31] SLV5CMPB — PWM5 Compare B 事件触发 Capture B 事件
  [30] SLV5CMPA — PWM5 Compare A 事件触发 Capture B 事件
  [29] SLV5CLRA — PWM5 OutA Clr 事件触发 Capture B 事件
  [28] SLV5SETA — PWM5 OutA Set 事件触发 Capture B 事件
  [27] SLV4CMPB — PWM4 Compare B 事件触发 Capture B 事件
  [26] SLV4CMPA — PWM4 Compare A 事件触发 Capture B 事件
  [25] SLV4CLRA — PWM4 OutA Clr 事件触发 Capture B 事件
  [24] SLV4SETA — PWM4 OutA Set 事件触发 Capture B 事件
  [23] SLV2CMPB — PWM2 Compare B 事件触发 Capture B 事件
  [22] SLV2CMPA — PWM2 Compare A 事件触发 Capture B 事件
  [21] SLV2CLRA — PWM2 OutA Clr 事件触发 Capture B 事件
  [20] SLV2SETA — PWM2 OutA Set 事件触发 Capture B 事件
  [19] SLV1CMPB — PWM1 Compare B 事件触发 Capture B 事件
  [18] SLV1CMPA — PWM1 Compare A 事件触发 Capture B 事件
  [17] SLV1CLRA — PWM1 OutA Clr 事件触发 Capture B 事件
  [16] SLV1SETA — PWM1 OutA Set 事件触发 Capture B 事件
  [15] SLV0CMPB — PWM0 Compare B 事件触发 Capture B 事件
  [14] SLV0CMPA — PWM0 Compare A 事件触发 Capture B 事件
  [13] SLV0CLRA — PWM0 OutA Clr 事件触发 Capture B 事件
  [12] SLV0SETA — PWM0 OutA Set 事件触发 Capture B 事件
  [n+2] EXTEVT{n} (n=0..9) — PWMx Event {n} 事件触发 Capture B 事件
  [1] UPDCPT — PWMx Update 事件触发 Capture B 事件
  [0] SWCPT — Software Capture 事件触发 Capture B 事件

## HRPWM_SLV4
Base 0x4003B500
Registers as HRPWM_SLV0; these are added or differ:
0x54 RSTR — HRPWM PWMx Reset Register
  [31] SLV5CMPB — PWM5 Compare B事件使 PWMx 计数器复位
  [3n+21] SLV{n}CMPD (n=0..3) — PWM{n} Compare D事件使 PWMx 计数器复位
  [3n+20] SLV{n}CMPB (n=0..3) — PWM{n} Compare B事件使 PWMx 计数器复位
  [3n+19] SLV{n}CMPA (n=0..3) — PWM{n} Compare A事件使 PWMx 计数器复位
  [18] SLVCMPD — PWMx Compare D事件使 PWMx 计数器复位
  [17] SLVCMPB — PWMx Compare B事件使 PWMx 计数器复位
  [16] SLVUPD — PWMx Update事件使 PWMx 计数器复位
  [n+6] EXTEVT{n} (n=0..9) — PWMx Event {n}事件使 PWMx 计数器复位
  [5] MSTPER — Master PWM Period事件使 PWMx 计数器复位
  [4] MSTCMPD — Master PWM Compare D事件使 PWMx 计数器复位
  [3] MSTCMPC — Master PWM Compare C事件使 PWMx 计数器复位
  [2] MSTCMPB — Master PWM Compare B事件使 PWMx 计数器复位
  [1] MSTCMPA — Master PWM Compare A事件使 PWMx 计数器复位
  [0] SLV5CMPA — PWM5 Compare A事件使 PWMx 计数器复位
0x60 CAPACR — HRPWM PWMx Capture A Control Register
  [31] SLV5CMPB — PWM5 Compare B 事件触发 Capture A 事件
  [30] SLV5CMPA — PWM5 Compare A 事件触发 Capture A 事件
  [29] SLV5CLRA — PWM5 OutA Clr 事件触发 Capture A 事件
  [28] SLV5SETA — PWM5 OutA Set 事件触发 Capture A 事件
  [4n+15] SLV{n}CMPB (n=0..3) — PWM{n} Compare B 事件触发 Capture A 事件
  [4n+14] SLV{n}CMPA (n=0..3) — PWM{n} Compare A 事件触发 Capture A 事件
  [4n+13] SLV{n}CLRA (n=0..3) — PWM{n} OutA Clr 事件触发 Capture A 事件
  [4n+12] SLV{n}SETA (n=0..3) — PWM{n} OutA Set 事件触发 Capture A 事件
  [n+2] EXTEVT{n} (n=0..9) — PWMx Event {n} 事件触发 Capture A 事件
  [1] UPDCPT — PWMx Update 事件触发 Capture A 事件
  [0] SWCPT — Software Capture 事件触发 Capture A 事件
0x68 CAPBCR — HRPWM PWMx Capture B Control Register
  [31] SLV5CMPB — PWM5 Compare B 事件触发 Capture B 事件
  [30] SLV5CMPA — PWM5 Compare A 事件触发 Capture B 事件
  [29] SLV5CLRA — PWM5 OutA Clr 事件触发 Capture B 事件
  [28] SLV5SETA — PWM5 OutA Set 事件触发 Capture B 事件
  [4n+15] SLV{n}CMPB (n=0..3) — PWM{n} Compare B 事件触发 Capture B 事件
  [4n+14] SLV{n}CMPA (n=0..3) — PWM{n} Compare A 事件触发 Capture B 事件
  [4n+13] SLV{n}CLRA (n=0..3) — PWM{n} OutA Clr 事件触发 Capture B 事件
  [4n+12] SLV{n}SETA (n=0..3) — PWM{n} OutA Set 事件触发 Capture B 事件
  [n+2] EXTEVT{n} (n=0..9) — PWMx Event {n} 事件触发 Capture B 事件
  [1] UPDCPT — PWMx Update 事件触发 Capture B 事件
  [0] SWCPT — Software Capture 事件触发 Capture B 事件

## HRPWM_SLV5
Base 0x4003B600
Registers as HRPWM_SLV0; these are added or differ:
0x54 RSTR — HRPWM PWMx Reset Register
  [31] SLV4CMPB — PWM4 Compare B事件使 PWMx 计数器复位
  [3n+21] SLV{n}CMPD (n=0..3) — PWM{n} Compare D事件使 PWMx 计数器复位
  [3n+20] SLV{n}CMPB (n=0..3) — PWM{n} Compare B事件使 PWMx 计数器复位
  [3n+19] SLV{n}CMPA (n=0..3) — PWM{n} Compare A事件使 PWMx 计数器复位
  [18] SLVCMPD — PWMx Compare D事件使 PWMx 计数器复位
  [17] SLVCMPB — PWMx Compare B事件使 PWMx 计数器复位
  [16] SLVUPD — PWMx Update事件使 PWMx 计数器复位
  [n+6] EXTEVT{n} (n=0..9) — PWMx Event {n}事件使 PWMx 计数器复位
  [5] MSTPER — Master PWM Period事件使 PWMx 计数器复位
  [4] MSTCMPD — Master PWM Compare D事件使 PWMx 计数器复位
  [3] MSTCMPC — Master PWM Compare C事件使 PWMx 计数器复位
  [2] MSTCMPB — Master PWM Compare B事件使 PWMx 计数器复位
  [1] MSTCMPA — Master PWM Compare A事件使 PWMx 计数器复位
  [0] SLV4CMPA — PWM4 Compare A事件使 PWMx 计数器复位
0x60 CAPACR — HRPWM PWMx Capture A Control Register
  [4n+15] SLV{n}CMPB (n=0..4) — PWM{n} Compare B 事件触发 Capture A 事件
  [4n+14] SLV{n}CMPA (n=0..4) — PWM{n} Compare A 事件触发 Capture A 事件
  [4n+13] SLV{n}CLRA (n=0..4) — PWM{n} OutA Clr 事件触发 Capture A 事件
  [4n+12] SLV{n}SETA (n=0..4) — PWM{n} OutA Set 事件触发 Capture A 事件
  [n+2] EXTEVT{n} (n=0..9) — PWMx Event {n} 事件触发 Capture A 事件
  [1] UPDCPT — PWMx Update 事件触发 Capture A 事件
  [0] SWCPT — Software Capture 事件触发 Capture A 事件
0x68 CAPBCR — HRPWM PWMx Capture B Control Register
  [4n+15] SLV{n}CMPB (n=0..4) — PWM{n} Compare B 事件触发 Capture B 事件
  [4n+14] SLV{n}CMPA (n=0..4) — PWM{n} Compare A 事件触发 Capture B 事件
  [4n+13] SLV{n}CLRA (n=0..4) — PWM{n} OutA Clr 事件触发 Capture B 事件
  [4n+12] SLV{n}SETA (n=0..4) — PWM{n} OutA Set 事件触发 Capture B 事件
  [n+2] EXTEVT{n} (n=0..9) — PWMx Event {n} 事件触发 Capture B 事件
  [1] UPDCPT — PWMx Update 事件触发 Capture B 事件
  [0] SWCPT — Software Capture 事件触发 Capture B 事件

## HRPWM_SLV6
Base 0x4003B700
Registers as HRPWM_SLV5; these are added or differ:
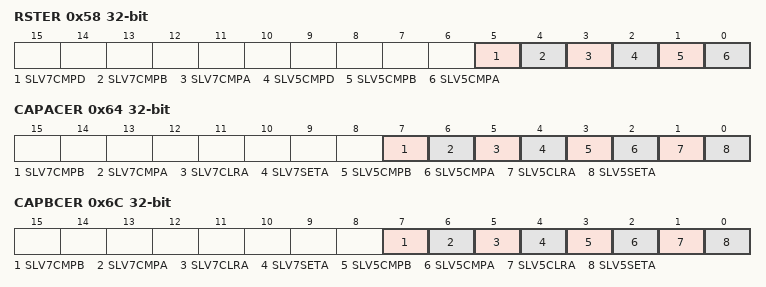
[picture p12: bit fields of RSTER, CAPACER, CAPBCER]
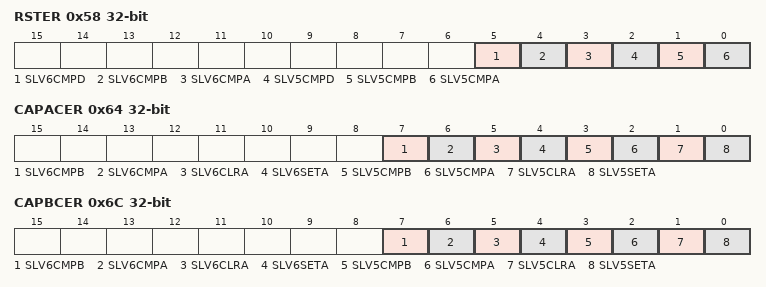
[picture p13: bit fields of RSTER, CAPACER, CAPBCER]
0x58 RSTER — HRPWM PWMx Reset Extended Register
  [5] SLV7CMPD — PWM7 Compare D事件使 PWMx 计数器复位
  [4] SLV7CMPB — PWM7 Compare B事件使 PWMx 计数器复位
  [3] SLV7CMPA — PWM7 Compare A事件使 PWMx 计数器复位
  [2] SLV5CMPD — PWM5 Compare D事件使 PWMx 计数器复位
  [1] SLV5CMPB — PWM5 Compare B事件使 PWMx 计数器复位
  [0] SLV5CMPA — PWM5 Compare A事件使 PWMx 计数器复位
0x64 CAPACER — HRPWM PWMx Capture A Control Extended Register
  [7] SLV7CMPB — PWM7 Compare B 事件触发 Capture A 事件
  [6] SLV7CMPA — PWM7 Compare A 事件触发 Capture A 事件
  [5] SLV7CLRA — PWM7 OutA Clr 事件触发 Capture A 事件
  [4] SLV7SETA — PWM7 OutA Set 事件触发 Capture A 事件
  [3] SLV5CMPB — PWM5 Compare B 事件触发 Capture A 事件
  [2] SLV5CMPA — PWM5 Compare A 事件触发 Capture A 事件
  [1] SLV5CLRA — PWM5 OutA Clr 事件触发 Capture A 事件
  [0] SLV5SETA — PWM5 OutA Set 事件触发 Capture A 事件
0x6C CAPBCER — HRPWM PWMx Capture B Control Extended Register
  [7] SLV7CMPB — PWM7 Compare B 事件触发 Capture B 事件
  [6] SLV7CMPA — PWM7 Compare A 事件触发 Capture B 事件
  [5] SLV7CLRA — PWM7 OutA Clr 事件触发 Capture B 事件
  [4] SLV7SETA — PWM7 OutA Set 事件触发 Capture B 事件
  [3] SLV5CMPB — PWM5 Compare B 事件触发 Capture B 事件
  [2] SLV5CMPA — PWM5 Compare A 事件触发 Capture B 事件
  [1] SLV5CLRA — PWM5 OutA Clr 事件触发 Capture B 事件
  [0] SLV5SETA — PWM5 OutA Set 事件触发 Capture B 事件

## HRPWM_SLV7
Base 0x4003B800
Registers as HRPWM_SLV5; these are added or differ:
0x58 RSTER — HRPWM PWMx Reset Extended Register
  [5] SLV6CMPD — PWM6 Compare D事件使 PWMx 计数器复位
  [4] SLV6CMPB — PWM6 Compare B事件使 PWMx 计数器复位
  [3] SLV6CMPA — PWM6 Compare A事件使 PWMx 计数器复位
  [2] SLV5CMPD — PWM5 Compare D事件使 PWMx 计数器复位
  [1] SLV5CMPB — PWM5 Compare B事件使 PWMx 计数器复位
  [0] SLV5CMPA — PWM5 Compare A事件使 PWMx 计数器复位
0x64 CAPACER — HRPWM PWMx Capture A Control Extended Register
  [7] SLV6CMPB — PWM6 Compare B 事件触发 Capture A 事件
  [6] SLV6CMPA — PWM6 Compare A 事件触发 Capture A 事件
  [5] SLV6CLRA — PWM6 OutA Clr 事件触发 Capture A 事件
  [4] SLV6SETA — PWM6 OutA Set 事件触发 Capture A 事件
  [3] SLV5CMPB — PWM5 Compare B 事件触发 Capture A 事件
  [2] SLV5CMPA — PWM5 Compare A 事件触发 Capture A 事件
  [1] SLV5CLRA — PWM5 OutA Clr 事件触发 Capture A 事件
  [0] SLV5SETA — PWM5 OutA Set 事件触发 Capture A 事件
0x6C CAPBCER — HRPWM PWMx Capture B Control Extended Register
  [7] SLV6CMPB — PWM6 Compare B 事件触发 Capture B 事件
  [6] SLV6CMPA — PWM6 Compare A 事件触发 Capture B 事件
  [5] SLV6CLRA — PWM6 OutA Clr 事件触发 Capture B 事件
  [4] SLV6SETA — PWM6 OutA Set 事件触发 Capture B 事件
  [3] SLV5CMPB — PWM5 Compare B 事件触发 Capture B 事件
  [2] SLV5CMPA — PWM5 Compare A 事件触发 Capture B 事件
  [1] SLV5CLRA — PWM5 OutA Clr 事件触发 Capture B 事件
  [0] SLV5SETA — PWM5 OutA Set 事件触发 Capture B 事件
